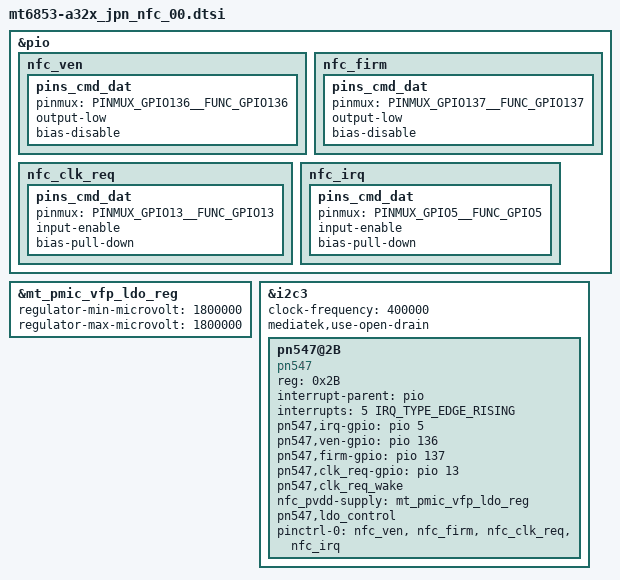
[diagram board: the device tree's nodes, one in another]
/* #include "../nfc_lsi.dtsi" */                     /* From nfc_lsi.py */
/*
 * This program is free software; you can redistribute it and/or modify
 * it under the terms of the GNU General Public License version 2 and
 * only version 2 as published by the Free Software Foundation.
 *
 * This program is distributed in the hope that it will be useful,
 * but WITHOUT ANY WARRANTY; without even the implied warranty of
 * MERCHANTABILITY or FITNESS FOR A PARTICULAR PURPOSE.  See the
 * GNU General Public License for more details.
 */

&pio {
	nfc_ven: nfc_ven {
		pins_cmd_dat {
			pinmux = <PINMUX_GPIO136__FUNC_GPIO136>;
			output-low;
			bias-disable;
		};
	};

	nfc_firm: nfc_firm {
		pins_cmd_dat {
			pinmux = <PINMUX_GPIO137__FUNC_GPIO137>;
			output-low;
			bias-disable;
		};
	};

	nfc_clk_req: nfc_clk_req {
		pins_cmd_dat {
			pinmux = <PINMUX_GPIO13__FUNC_GPIO13>;
			input-enable;
			bias-pull-down;
		};
	};

	nfc_irq: nfc_irq {
		pins_cmd_dat {
			pinmux = <PINMUX_GPIO5__FUNC_GPIO5>;
			input-enable;
			bias-pull-down;
		};
	};
};

&mt_pmic_vfp_ldo_reg {
	regulator-min-microvolt = <1800000>;
	regulator-max-microvolt = <1800000>;
};

&i2c3 {
	status = "ok";
	clock-frequency = <400000>;
	mediatek,use-open-drain;

	pn547@2B {
		compatible = "pn547";
		reg = <0x2B>;

		interrupt-parent = <&pio>;
		interrupts = <5 IRQ_TYPE_EDGE_RISING>;

		pn547,irq-gpio = <&pio 5 0>;
		pn547,ven-gpio = <&pio 136 0>;
		pn547,firm-gpio = <&pio 137 0>;
		pn547,clk_req-gpio = <&pio 13 0>;
		pn547,clk_req_wake;

		nfc_pvdd-supply = <&mt_pmic_vfp_ldo_reg>;
		pn547,ldo_control;

		pinctrl-names = "default";
		pinctrl-0 = <&nfc_ven &nfc_firm &nfc_clk_req &nfc_irq>;
	};
};

#if 0
/* func2 - CLK:GPIO55, CS:56, MOSI:57, MISO:58 */
&spi3 {
	status = "okay";

	ese_spi@0 {
		compatible = "p61";
		spi-max-frequency = <13000000>;

		/*p3-vdd-1p8= "VDD_ESE_SEN4";*/
		p61-ap_vendor = "mtk";
		p61-spi_node = <&spi3>;

		/*ese_p3,cs-gpio = <&gpp7 3 0>;*/
	};
};
#endif
